# STM32G030 register map
File version: 1.6
CPU: CM0 r0p1, little endian, MPU, no FPU, 2 interrupt priority bits
Registers are 32-bit, read-write, reset 0x0 unless marked. A register's access mark holds for its fields unless they carry their own. Offsets are from the block's base; [hi:lo] are bit positions; {n}, {i} and the like mark numbered series.

## TAMP — Tamper and backup registers
Base 0x4000B000
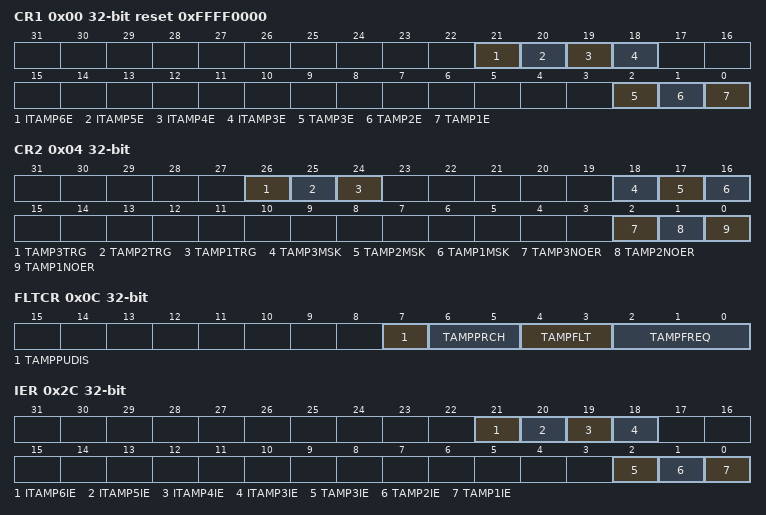
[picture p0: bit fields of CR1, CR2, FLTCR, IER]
0x00 CR1 reset 0xFFFF0000 — TAMP control register 1
  [21] ITAMP6E — Internal tamper 6 enable: ST manufacturer readout
  [20] ITAMP5E — Internal tamper 5 enable: RTC calendar overflow
  [19] ITAMP4E — Internal tamper 4 enable: HSE monitoring
  [18] ITAMP3E — Internal tamper 3 enable: LSE monitoring
  [2] TAMP3E — Tamper detection on TAMP_IN3 enable
  [1] TAMP2E — Tamper detection on TAMP_IN2 enable
  [0] TAMP1E — Tamper detection on TAMP_IN1 enable
0x04 CR2 — TAMP control register 2
  [26] TAMP3TRG — Active level for tamper 3 input (active mode disabled) If TAMPFLT = 00 Tamper 3 input rising edge and high level triggers a tamper detection event. If TAMPFLT = 00 Tamper 3 input falling edge and low level triggers a tamper detection event.
  [25] TAMP2TRG — Active level for tamper 2 input (active mode disabled) If TAMPFLT = 00 Tamper 2 input rising edge and high level triggers a tamper detection event. If TAMPFLT = 00 Tamper 2 input falling edge and low level triggers a tamper detection event.
  [24] TAMP1TRG — Active level for tamper 1 input (active mode disabled) If TAMPFLT = 00 Tamper 1 input rising edge and high level triggers a tamper detection event. If TAMPFLT = 00 Tamper 1 input falling edge and low level triggers a tamper detection event.
  [18] TAMP3MSK — Tamper 3 mask The tamper 3 interrupt must not be enabled when TAMP3MSK is set.
  [17] TAMP2MSK — Tamper 2 mask The tamper 2 interrupt must not be enabled when TAMP2MSK is set.
  [16] TAMP1MSK — Tamper 1 mask The tamper 1 interrupt must not be enabled when TAMP1MSK is set.
  [2] TAMP3NOER — Tamper 3 no erase
  [1] TAMP2NOER — Tamper 2 no erase
  [0] TAMP1NOER — Tamper 1 no erase
0x0C FLTCR — TAMP filter control register
  [7] TAMPPUDIS — TAMP_INx pull-up disable This bit determines if each of the TAMPx pins are precharged before each sample.
  [6:5] TAMPPRCH — TAMP_INx precharge duration These bit determines the duration of time during which the pull-up/is activated before each sample. TAMPPRCH is valid for each of the TAMP_INx inputs.
  [4:3] TAMPFLT — TAMP_INx filter count These bits determines the number of consecutive samples at the specified level (TAMP*TRG) needed to activate a tamper event. TAMPFLT is valid for each of the TAMP_INx inputs.
  [2:0] TAMPFREQ — Tamper sampling frequency Determines the frequency at which each of the TAMP_INx inputs are sampled.
0x2C IER — TAMP interrupt enable register
  [21] ITAMP6IE — Internal tamper 6 interrupt enable: ST manufacturer readout
  [20] ITAMP5IE — Internal tamper 5 interrupt enable: RTC calendar overflow
  [19] ITAMP4IE — Internal tamper 4 interrupt enable: HSE monitoring
  [18] ITAMP3IE — Internal tamper 3 interrupt enable: LSE monitoring
  [2] TAMP3IE — Tamper 3 interrupt enable
  [1] TAMP2IE — Tamper 2 interrupt enable
  [0] TAMP1IE — Tamper 1 interrupt enable
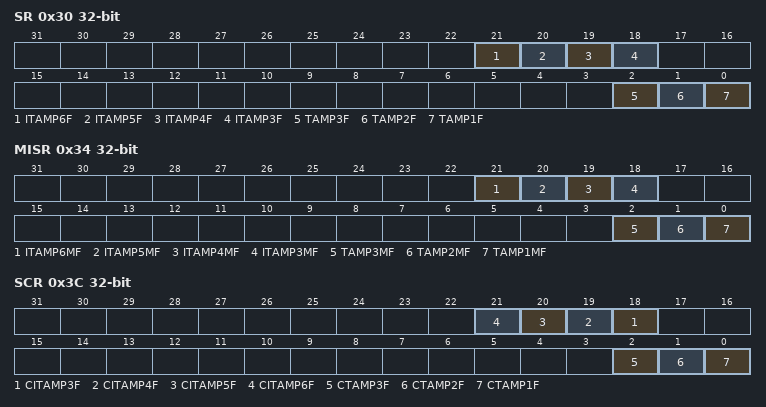
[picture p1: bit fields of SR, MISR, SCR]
0x30 SR ro — TAMP status register
  [21] ITAMP6F — ST manufacturer readout tamper detection flag This flag is set by hardware when a tamper detection event is detected on the internal tamper 6.
  [20] ITAMP5F — RTC calendar overflow tamper detection flag This flag is set by hardware when a tamper detection event is detected on the internal tamper 5.
  [19] ITAMP4F — HSE monitoring tamper detection flag This flag is set by hardware when a tamper detection event is detected on the internal tamper 4.
  [18] ITAMP3F — LSE monitoring tamper detection flag This flag is set by hardware when a tamper detection event is detected on the internal tamper 3.
  [2] TAMP3F — TAMP3 detection flag This flag is set by hardware when a tamper detection event is detected on the TAMP3 input.
  [1] TAMP2F — TAMP2 detection flag This flag is set by hardware when a tamper detection event is detected on the TAMP2 input.
  [0] TAMP1F — TAMP1 detection flag This flag is set by hardware when a tamper detection event is detected on the TAMP1 input.
0x34 MISR ro — TAMP masked interrupt status register
  [21] ITAMP6MF — ST manufacturer readout tamper interrupt masked flag This flag is set by hardware when the internal tamper 6 interrupt is raised.
  [20] ITAMP5MF — RTC calendar overflow tamper interrupt masked flag This flag is set by hardware when the internal tamper 5 interrupt is raised.
  [19] ITAMP4MF — HSE monitoring tamper interrupt masked flag This flag is set by hardware when the internal tamper 4 interrupt is raised.
  [18] ITAMP3MF — LSE monitoring tamper interrupt masked flag This flag is set by hardware when the internal tamper 3 interrupt is raised.
  [2] TAMP3MF — TAMP3 interrupt masked flag This flag is set by hardware when the tamper 3 interrupt is raised.
  [1] TAMP2MF — TAMP2 interrupt masked flag This flag is set by hardware when the tamper 2 interrupt is raised.
  [0] TAMP1MF — TAMP1 interrupt masked flag This flag is set by hardware when the tamper 1 interrupt is raised.
0x3C SCR wo — TAMP status clear register
  [n+15] CITAMP{n}F (n=3..6) — Clear ITAMP{n} detection flag Writing 1 in this bit clears the ITAMP{n}F bit in the TAMP_SR register.
  [2] CTAMP3F — Clear TAMP3 detection flag Writing 1 in this bit clears the TAMP3F bit in the TAMP_SR register.
  [1] CTAMP2F — Clear TAMP2 detection flag Writing 1 in this bit clears the TAMP2F bit in the TAMP_SR register.
  [0] CTAMP1F — Clear TAMP1 detection flag Writing 1 in this bit clears the TAMP1F bit in the TAMP_SR register.
{0x100+4i} BKP{i}R (i=0..4) — TAMP backup {i} register
  [31:0] BKP — The application can write or read data to and from these registers. They are powered-on by VBAT when VDD is switched off, so that they are not reset by System reset, and their contents remain valid when the device operates in low-power mode. In the default configuration this register is reset on a tamper detection event. It is forced to reset value as long as there is at least one internal or external tamper flag being set. This register is also reset when the readout protection (RDP) is disabled.
